VERSION ""

NS_ :

BS_:

BU_: XXX

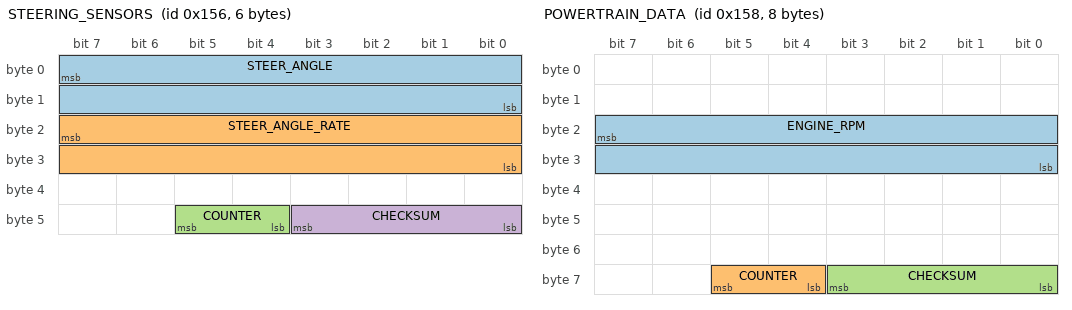
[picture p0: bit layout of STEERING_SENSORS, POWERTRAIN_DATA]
BO_ 342 STEERING_SENSORS: 6 EPS
 SG_ STEER_ANGLE : 7|16@0- (-0.1,0) [-500|500] "deg"  NEO
 SG_ STEER_ANGLE_RATE : 23|16@0- (1,0) [-3000|3000] "deg/s"  NEO
 SG_ COUNTER : 45|2@0+ (1,0) [0|3] ""  NEO
 SG_ CHECKSUM : 43|4@0+ (1,0) [0|3] ""  NEO

BO_ 344 POWERTRAIN_DATA: 8 PCM
 SG_ ENGINE_RPM : 23|16@0+ (1,0) [0|15000] "rpm"  NEO
 SG_ COUNTER : 61|2@0+ (1,0) [0|3] ""  NEO
 SG_ CHECKSUM : 59|4@0+ (1,0) [0|3] ""  NEO

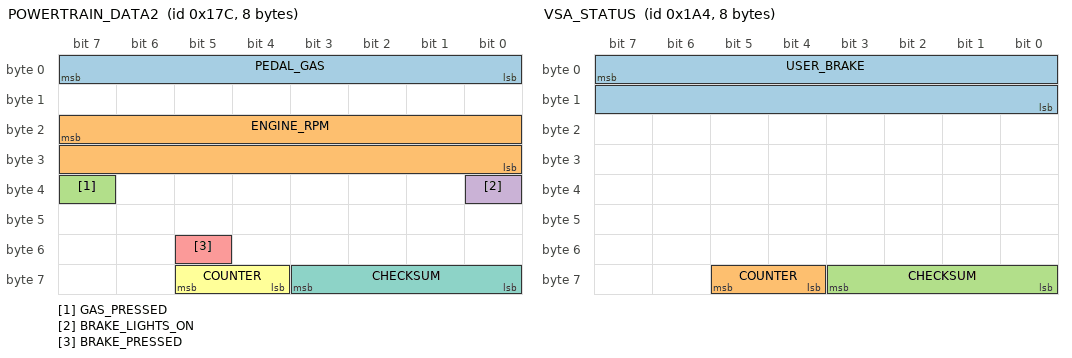
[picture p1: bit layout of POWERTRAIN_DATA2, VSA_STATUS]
BO_ 380 POWERTRAIN_DATA2: 8 PCM
 SG_ PEDAL_GAS : 7|8@0+ (1,0) [0|255] ""  NEO
 SG_ ENGINE_RPM : 23|16@0+ (1,0) [0|15000] "rpm"  NEO
 SG_ GAS_PRESSED : 39|1@0+ (1,0) [0|1] ""  NEO
 SG_ BRAKE_LIGHTS_ON : 32|1@0+ (1,0) [0|1] "rpm"  NEO
 SG_ BRAKE_PRESSED : 53|1@0+ (1,0) [0|1] ""  NEO
 SG_ COUNTER : 61|2@0+ (1,0) [0|3] ""  NEO
 SG_ CHECKSUM : 59|4@0+ (1,0) [0|3] ""  NEO

BO_ 420 VSA_STATUS: 8 VSA
 SG_ USER_BRAKE : 7|16@0+ (0.015625,-1.609375) [0|1000] ""  NEO
 SG_ COUNTER : 61|2@0+ (1,0) [0|3] ""  NEO
 SG_ CHECKSUM : 59|4@0+ (1,0) [0|3] ""  NEO

BO_ 422 Brights: 8 XXX
 SG_ BrightHeadlights : 0|1@1+ (1,0) [0|3] "" XXX

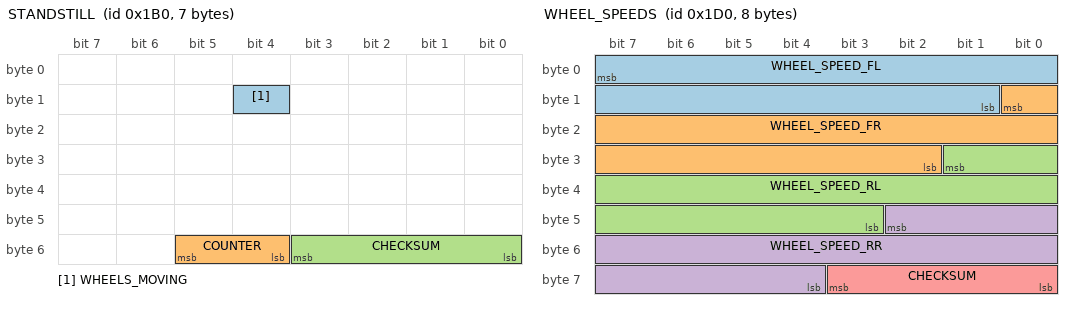
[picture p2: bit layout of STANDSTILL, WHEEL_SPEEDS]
BO_ 432 STANDSTILL: 7 VSA
 SG_ WHEELS_MOVING : 12|1@0+ (1,0) [0|1] ""  NEO
 SG_ COUNTER : 53|2@0+ (1,0) [0|3] ""  NEO
 SG_ CHECKSUM : 51|4@0+ (1,0) [0|3] ""  NEO

BO_ 464 WHEEL_SPEEDS: 8 VSA
 SG_ WHEEL_SPEED_FL : 7|15@0+ (0.002759506,0) [0|70] "m/s"  NEO
 SG_ WHEEL_SPEED_FR : 8|15@0+ (0.002759506,0) [0|70] "m/s"  NEO
 SG_ WHEEL_SPEED_RL : 25|15@0+ (0.002759506,0) [0|70] "m/s"  NEO
 SG_ WHEEL_SPEED_RR : 42|15@0+ (0.002759506,0) [0|70] "m/s"  NEO
 SG_ CHECKSUM : 59|4@0+ (1,0) [0|3] ""  NEO

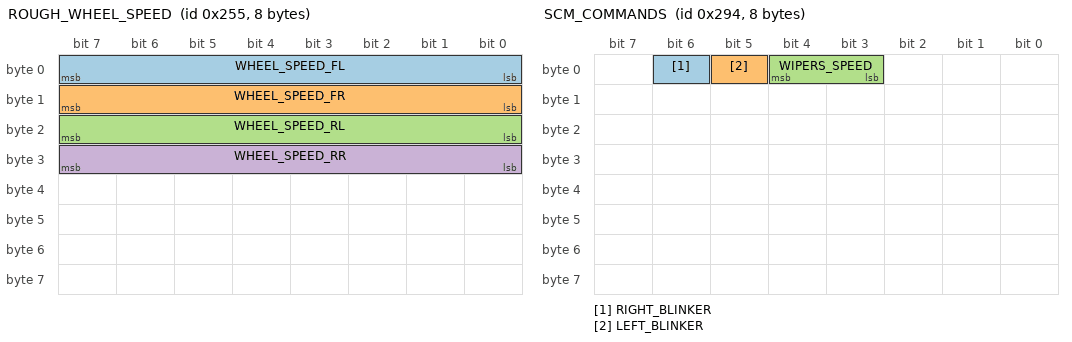
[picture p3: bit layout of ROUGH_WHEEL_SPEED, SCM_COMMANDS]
BO_ 597 ROUGH_WHEEL_SPEED: 8 VSA
 SG_ WHEEL_SPEED_FL : 7|8@0+ (1,0) [0|255] "mph"  NEO
 SG_ WHEEL_SPEED_FR : 15|8@0+ (1,0) [0|255] "mph"  NEO
 SG_ WHEEL_SPEED_RL : 23|8@0+ (1,0) [0|255] "mph"  NEO
 SG_ WHEEL_SPEED_RR : 31|8@0+ (1,0) [0|255] "mph"  NEO

BO_ 660 SCM_COMMANDS: 8 SCM
 SG_ RIGHT_BLINKER : 6|1@0+ (1,0) [0|1] ""  NEO
 SG_ LEFT_BLINKER : 5|1@0+ (1,0) [0|1] ""  NEO
 SG_ WIPERS_SPEED : 4|2@0+ (1,0) [0|3] ""  NEO

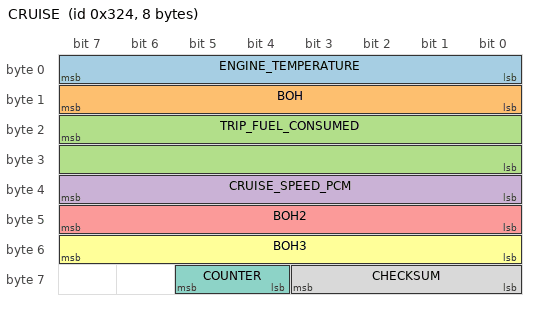
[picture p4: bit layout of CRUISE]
BO_ 804 CRUISE: 8 PCM
 SG_ ENGINE_TEMPERATURE : 7|8@0+ (1,0) [0|255] ""  NEO
 SG_ BOH : 15|8@0+ (1,0) [0|255] ""  NEO
 SG_ TRIP_FUEL_CONSUMED : 23|16@0+ (1,0) [0|255] ""  NEO
 SG_ CRUISE_SPEED_PCM : 39|8@0+ (1,0) [0|255] ""  NEO
 SG_ BOH2 : 47|8@0- (1,0) [0|255] ""  NEO
 SG_ BOH3 : 55|8@0+ (1,0) [0|255] ""  NEO
 SG_ COUNTER : 61|2@0+ (1,0) [0|3] ""  NEO
 SG_ CHECKSUM : 59|4@0+ (1,0) [0|3] ""  NEO

BO_ 985 NEW_MSG_2: 8 XXX
 SG_ NEW_SIGNAL_1 : 21|6@0+ (1,0) [0|63] "" XXX

BO_ 804 NEW_MSG_3: 8 XXX
 SG_ EngineTempMaybe : 31|8@0+ (1,0) [0|255] "" XXX

BO_ 145 NEW_MSG_4: 8 XXX
 SG_ NEW_SIGNAL_1 : 31|8@0+ (1,0) [0|255] "" XXX
